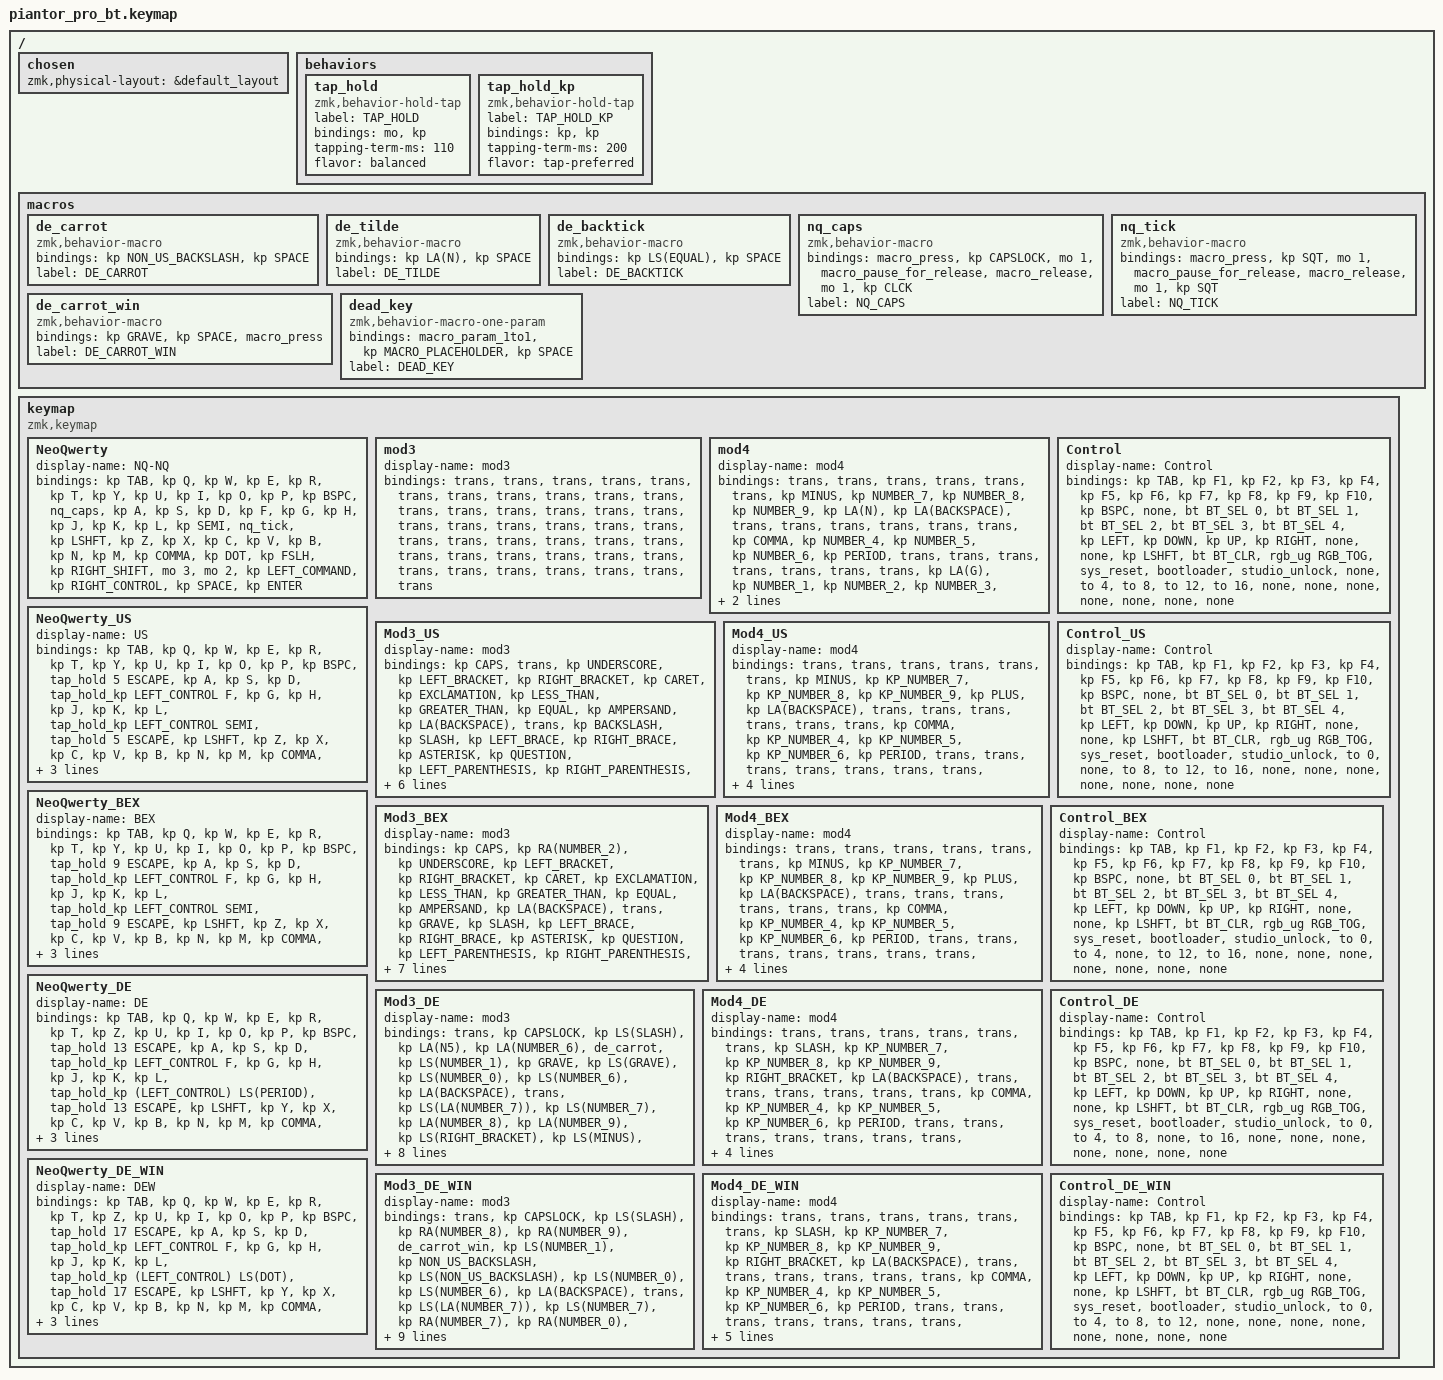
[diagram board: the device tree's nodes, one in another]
/*
 * Copyright (c) 2020 The ZMK Contributors
 *
 * SPDX-License-Identifier: MIT
 */

#include <behaviors.dtsi>
#include <dt-bindings/zmk/bt.h>
#include <dt-bindings/zmk/keys.h>
#include <dt-bindings/zmk/rgb.h>

/ {
    chosen { zmk,physical-layout = &default_layout; };
};

/ {
    behaviors {
        tap_hold: tap_hold {
            compatible = "zmk,behavior-hold-tap";
            label = "TAP_HOLD";
            bindings = <&mo>, <&kp>;

            #binding-cells = <2>;
            tapping-term-ms = <110>;
            flavor = "balanced";
        };

        tap_hold_kp: tap_hold_kp {
            compatible = "zmk,behavior-hold-tap";
            label = "TAP_HOLD_KP";
            bindings = <&kp>, <&kp>;

            #binding-cells = <2>;
            tapping-term-ms = <200>;
            flavor = "tap-preferred";
        };
    };

    macros {
        de_carrot: de_carrot {
            compatible = "zmk,behavior-macro";
            #binding-cells = <0>;
            bindings = <&kp NON_US_BACKSLASH &kp SPACE>;
            label = "DE_CARROT";
        };

        de_tilde: de_tilde {
            compatible = "zmk,behavior-macro";
            #binding-cells = <0>;
            bindings = <&kp LA(N) &kp SPACE>;
            label = "DE_TILDE";
        };

        de_backtick: de_backtick {
            compatible = "zmk,behavior-macro";
            #binding-cells = <0>;
            bindings = <&kp LS(EQUAL) &kp SPACE>;
            label = "DE_BACKTICK";
        };

        nq_caps: nq_caps {
            compatible = "zmk,behavior-macro";
            #binding-cells = <0>;
            bindings =
                <&macro_press>,
                <&kp CAPSLOCK &mo 1>,
                <&macro_pause_for_release>,
                <&macro_release>,
                <&mo 1 &kp CLCK>;

            label = "NQ_CAPS";
        };

        nq_tick: nq_tick {
            compatible = "zmk,behavior-macro";
            #binding-cells = <0>;
            bindings =
                <&macro_press>,
                <&kp SQT &mo 1>,
                <&macro_pause_for_release>,
                <&macro_release>,
                <&mo 1 &kp SQT>;

            label = "NQ_TICK";
        };

        de_carrot_win: de_carrot_win {
            compatible = "zmk,behavior-macro";
            #binding-cells = <0>;
            bindings = <&kp GRAVE &kp SPACE>, <&macro_press>;

            label = "DE_CARROT_WIN";
        };

        dead_key: dead_key {
            compatible = "zmk,behavior-macro-one-param";
            #binding-cells = <1>;
            bindings = <&macro_param_1to1 &kp MACRO_PLACEHOLDER &kp SPACE>;
            label = "DEAD_KEY";
        };
    };

    keymap {
        compatible = "zmk,keymap";

        NeoQwerty {
            display-name = "NQ-NQ";
            bindings = <
&kp TAB  &kp Q  &kp W  &kp E  &kp R  &kp T  &kp Y  &kp U  &kp I  &kp O  &kp P  &kp BSPC  &nq_caps  &kp A  &kp S  &kp D  &kp F  &kp G  &kp H  &kp J  &kp K  &kp L  &kp SEMI  &nq_tick  &kp LSHFT  &kp Z  &kp X  &kp C  &kp V  &kp B  &kp N  &kp M  &kp COMMA  &kp DOT  &kp FSLH  &kp RIGHT_SHIFT  &mo 3  &mo 2  &kp LEFT_COMMAND  &kp RIGHT_CONTROL  &kp SPACE  &kp ENTER
            >;
        };

        mod3 {
            display-name = "mod3";
            bindings = <
&trans  &trans  &trans  &trans  &trans  &trans  &trans  &trans  &trans  &trans  &trans  &trans  &trans  &trans  &trans  &trans  &trans  &trans  &trans  &trans  &trans  &trans  &trans  &trans  &trans  &trans  &trans  &trans  &trans  &trans  &trans  &trans  &trans  &trans  &trans  &trans  &trans  &trans  &trans  &trans  &trans  &trans
            >;
        };

        mod4 {
            display-name = "mod4";
            bindings = <
&trans  &trans  &trans  &trans  &trans  &trans  &kp MINUS  &kp NUMBER_7  &kp NUMBER_8  &kp NUMBER_9  &kp LA(N)  &kp LA(BACKSPACE)  &trans  &trans  &trans  &trans  &trans  &trans  &kp COMMA  &kp NUMBER_4  &kp NUMBER_5  &kp NUMBER_6  &kp PERIOD  &trans  &trans  &trans  &trans  &trans  &trans  &trans  &kp LA(G)  &kp NUMBER_1  &kp NUMBER_2  &kp NUMBER_3  &kp SLASH  &kp KP_NUMLOCK  &trans  &trans  &trans  &kp SPACE  &kp NUMBER_0  &trans
            >;
        };

        Control {
            display-name = "Control";
            bindings = <
&kp TAB  &kp F1  &kp F2  &kp F3  &kp F4  &kp F5  &kp F6  &kp F7  &kp F8  &kp F9  &kp F10  &kp BSPC  &none  &bt BT_SEL 0  &bt BT_SEL 1  &bt BT_SEL 2  &bt BT_SEL 3  &bt BT_SEL 4  &kp LEFT  &kp DOWN  &kp UP  &kp RIGHT  &none  &none  &kp LSHFT  &bt BT_CLR  &rgb_ug RGB_TOG  &sys_reset  &bootloader  &studio_unlock  &none  &to 4  &to 8  &to 12  &to 16  &none  &none  &none  &none  &none  &none  &none
            >;
        };

        NeoQwerty_US {
            display-name = "US";
            bindings = <
&kp TAB  &kp Q  &kp W  &kp E  &kp R  &kp T  &kp Y  &kp U  &kp I  &kp O  &kp P  &kp BSPC  &tap_hold 5 ESCAPE  &kp A  &kp S  &kp D  &tap_hold_kp LEFT_CONTROL F  &kp G  &kp H  &kp J  &kp K  &kp L  &tap_hold_kp LEFT_CONTROL SEMI  &tap_hold 5 ESCAPE  &kp LSHFT  &kp Z  &kp X  &kp C  &kp V  &kp B  &kp N  &kp M  &kp COMMA  &kp DOT  &kp FSLH  &kp RIGHT_SHIFT  &mo 7  &mo 6  &kp LEFT_COMMAND  &kp LEFT_ALT  &kp SPACE  &kp ENTER
            >;
        };

        Mod3_US {
            display-name = "mod3";
            bindings = <
&kp CAPS  &trans  &kp UNDERSCORE  &kp LEFT_BRACKET  &kp RIGHT_BRACKET  &kp CARET  &kp EXCLAMATION  &kp LESS_THAN  &kp GREATER_THAN  &kp EQUAL  &kp AMPERSAND  &kp LA(BACKSPACE)  &trans  &kp BACKSLASH  &kp SLASH  &kp LEFT_BRACE  &kp RIGHT_BRACE  &kp ASTERISK  &kp QUESTION  &kp LEFT_PARENTHESIS  &kp RIGHT_PARENTHESIS  &kp MINUS  &kp COLON  &trans  &kp RA(S)  &kp HASH  &kp DOLLAR  &kp PIPE  &kp TILDE  &kp GRAVE  &kp PLUS  &kp PERCENT  &kp DOUBLE_QUOTES  &kp SINGLE_QUOTE  &kp SEMICOLON  &kp AT_SIGN  &trans  &trans  &trans  &trans  &trans  &trans
            >;
        };

        Mod4_US {
            display-name = "mod4";
            bindings = <
&trans  &trans  &trans  &trans  &trans  &trans  &kp MINUS  &kp KP_NUMBER_7  &kp KP_NUMBER_8  &kp KP_NUMBER_9  &kp PLUS  &kp LA(BACKSPACE)  &trans  &trans  &trans  &trans  &trans  &trans  &kp COMMA  &kp KP_NUMBER_4  &kp KP_NUMBER_5  &kp KP_NUMBER_6  &kp PERIOD  &trans  &trans  &trans  &trans  &trans  &trans  &trans  &kp ASTERISK  &kp KP_NUMBER_1  &kp KP_NUMBER_2  &kp KP_NUMBER_3  &kp SLASH  &kp KP_NUMLOCK  &trans  &trans  &trans  &trans  &kp KP_NUMBER_0  &trans
            >;
        };

        Control_US {
            display-name = "Control";
            bindings = <
&kp TAB  &kp F1  &kp F2  &kp F3  &kp F4  &kp F5  &kp F6  &kp F7  &kp F8  &kp F9  &kp F10  &kp BSPC  &none  &bt BT_SEL 0  &bt BT_SEL 1  &bt BT_SEL 2  &bt BT_SEL 3  &bt BT_SEL 4  &kp LEFT  &kp DOWN  &kp UP  &kp RIGHT  &none  &none  &kp LSHFT  &bt BT_CLR  &rgb_ug RGB_TOG  &sys_reset  &bootloader  &studio_unlock  &to 0  &none  &to 8  &to 12  &to 16  &none  &none  &none  &none  &none  &none  &none
            >;
        };

        NeoQwerty_BEX {
            display-name = "BEX";
            bindings = <
&kp TAB  &kp Q  &kp W  &kp E  &kp R  &kp T  &kp Y  &kp U  &kp I  &kp O  &kp P  &kp BSPC  &tap_hold 9 ESCAPE  &kp A  &kp S  &kp D  &tap_hold_kp LEFT_CONTROL F  &kp G  &kp H  &kp J  &kp K  &kp L  &tap_hold_kp LEFT_CONTROL SEMI  &tap_hold 9 ESCAPE  &kp LSHFT  &kp Z  &kp X  &kp C  &kp V  &kp B  &kp N  &kp M  &kp COMMA  &kp DOT  &kp FSLH  &kp RIGHT_SHIFT  &mo 11  &mo 10  &kp LEFT_COMMAND  &kp LEFT_ALT  &kp SPACE  &kp ENTER
            >;
        };

        Mod3_BEX {
            display-name = "mod3";
            bindings = <
&kp CAPS  &kp RA(NUMBER_2)  &kp UNDERSCORE  &kp LEFT_BRACKET  &kp RIGHT_BRACKET  &kp CARET  &kp EXCLAMATION  &kp LESS_THAN  &kp GREATER_THAN  &kp EQUAL  &kp AMPERSAND  &kp LA(BACKSPACE)  &trans  &kp GRAVE  &kp SLASH  &kp LEFT_BRACE  &kp RIGHT_BRACE  &kp ASTERISK  &kp QUESTION  &kp LEFT_PARENTHESIS  &kp RIGHT_PARENTHESIS  &kp MINUS  &kp COLON  &trans  &kp RA(S)  &kp BACKSLASH  &kp DOLLAR  &kp LS(NON_US_BACKSLASH)  &kp LS(BACKSLASH)  &kp RA(RS(SQT))  &kp PLUS  &kp PERCENT  &kp RS(NUMBER_2)  &kp SINGLE_QUOTE  &kp SEMICOLON  &kp RS(SQT)  &trans  &trans  &trans  &trans  &trans  &trans
            >;
        };

        Mod4_BEX {
            display-name = "mod4";
            bindings = <
&trans  &trans  &trans  &trans  &trans  &trans  &kp MINUS  &kp KP_NUMBER_7  &kp KP_NUMBER_8  &kp KP_NUMBER_9  &kp PLUS  &kp LA(BACKSPACE)  &trans  &trans  &trans  &trans  &trans  &trans  &kp COMMA  &kp KP_NUMBER_4  &kp KP_NUMBER_5  &kp KP_NUMBER_6  &kp PERIOD  &trans  &trans  &trans  &trans  &trans  &trans  &trans  &kp ASTERISK  &kp KP_NUMBER_1  &kp KP_NUMBER_2  &kp KP_NUMBER_3  &kp SLASH  &kp KP_NUMLOCK  &trans  &trans  &trans  &trans  &kp KP_NUMBER_0  &trans
            >;
        };

        Control_BEX {
            display-name = "Control";
            bindings = <
&kp TAB  &kp F1  &kp F2  &kp F3  &kp F4  &kp F5  &kp F6  &kp F7  &kp F8  &kp F9  &kp F10  &kp BSPC  &none  &bt BT_SEL 0  &bt BT_SEL 1  &bt BT_SEL 2  &bt BT_SEL 3  &bt BT_SEL 4  &kp LEFT  &kp DOWN  &kp UP  &kp RIGHT  &none  &none  &kp LSHFT  &bt BT_CLR  &rgb_ug RGB_TOG  &sys_reset  &bootloader  &studio_unlock  &to 0  &to 4  &none  &to 12  &to 16  &none  &none  &none  &none  &none  &none  &none
            >;
        };

        NeoQwerty_DE {
            display-name = "DE";
            bindings = <
&kp TAB  &kp Q  &kp W  &kp E  &kp R  &kp T  &kp Z  &kp U  &kp I  &kp O  &kp P  &kp BSPC  &tap_hold 13 ESCAPE  &kp A  &kp S  &kp D  &tap_hold_kp LEFT_CONTROL F  &kp G  &kp H  &kp J  &kp K  &kp L  &tap_hold_kp (LEFT_CONTROL) LS(PERIOD)  &tap_hold 13 ESCAPE  &kp LSHFT  &kp Y  &kp X  &kp C  &kp V  &kp B  &kp N  &kp M  &kp COMMA  &kp DOT  &kp FSLH  &kp RIGHT_SHIFT  &mo 15  &mo 14  &kp LEFT_COMMAND  &kp LEFT_ALT  &kp SPACE  &kp ENTER
            >;
        };

        Mod3_DE {
            display-name = "mod3";
            bindings = <
&trans  &kp CAPSLOCK  &kp LS(SLASH)  &kp LA(N5)  &kp LA(NUMBER_6)  &de_carrot  &kp LS(NUMBER_1)  &kp GRAVE  &kp LS(GRAVE)  &kp LS(NUMBER_0)  &kp LS(NUMBER_6)  &kp LA(BACKSPACE)  &trans  &kp LS(LA(NUMBER_7))  &kp LS(NUMBER_7)  &kp LA(NUMBER_8)  &kp LA(NUMBER_9)  &kp LS(RIGHT_BRACKET)  &kp LS(MINUS)  &kp LS(N8)  &kp LS(N9)  &kp SLASH  &kp LS(PERIOD)  &trans  &trans  &kp NON_US_BACKSLASH  &kp LS(NUMBER_4)  &kp LA(NUMBER_7)  &de_tilde  &de_backtick  &kp RIGHT_BRACKET  &kp LS(NUMBER_5)  &kp RS(NUMBER_2)  &kp LS(BACKSLASH)  &kp LS(COMMA)  &kp LA(L)  &trans  &trans  &trans  &trans  &trans  &trans
            >;
        };

        Mod4_DE {
            display-name = "mod4";
            bindings = <
&trans  &trans  &trans  &trans  &trans  &trans  &kp SLASH  &kp KP_NUMBER_7  &kp KP_NUMBER_8  &kp KP_NUMBER_9  &kp RIGHT_BRACKET  &kp LA(BACKSPACE)  &trans  &trans  &trans  &trans  &trans  &trans  &kp COMMA  &kp KP_NUMBER_4  &kp KP_NUMBER_5  &kp KP_NUMBER_6  &kp PERIOD  &trans  &trans  &trans  &trans  &trans  &trans  &trans  &kp LS(RIGHT_BRACKET)  &kp KP_NUMBER_1  &kp KP_NUMBER_2  &kp KP_NUMBER_3  &kp LS(NUMBER_7)  &kp KP_NUMLOCK  &trans  &trans  &trans  &trans  &kp KP_NUMBER_0  &trans
            >;
        };

        Control_DE {
            display-name = "Control";
            bindings = <
&kp TAB  &kp F1  &kp F2  &kp F3  &kp F4  &kp F5  &kp F6  &kp F7  &kp F8  &kp F9  &kp F10  &kp BSPC  &none  &bt BT_SEL 0  &bt BT_SEL 1  &bt BT_SEL 2  &bt BT_SEL 3  &bt BT_SEL 4  &kp LEFT  &kp DOWN  &kp UP  &kp RIGHT  &none  &none  &kp LSHFT  &bt BT_CLR  &rgb_ug RGB_TOG  &sys_reset  &bootloader  &studio_unlock  &to 0  &to 4  &to 8  &none  &to 16  &none  &none  &none  &none  &none  &none  &none
            >;
        };

        NeoQwerty_DE_WIN {
            display-name = "DEW";
            bindings = <
&kp TAB  &kp Q  &kp W  &kp E  &kp R  &kp T  &kp Z  &kp U  &kp I  &kp O  &kp P  &kp BSPC  &tap_hold 17 ESCAPE  &kp A  &kp S  &kp D  &tap_hold_kp LEFT_CONTROL F  &kp G  &kp H  &kp J  &kp K  &kp L  &tap_hold_kp (LEFT_CONTROL) LS(DOT)  &tap_hold 17 ESCAPE  &kp LSHFT  &kp Y  &kp X  &kp C  &kp V  &kp B  &kp N  &kp M  &kp COMMA  &kp DOT  &kp FSLH  &kp RIGHT_SHIFT  &mo 19  &mo 18  &kp LEFT_COMMAND  &kp LEFT_ALT  &kp SPACE  &kp ENTER
            >;
        };

        Mod3_DE_WIN {
            display-name = "mod3";
            bindings = <
&trans  &kp CAPSLOCK  &kp LS(SLASH)  &kp RA(NUMBER_8)  &kp RA(NUMBER_9)  &de_carrot_win  &kp LS(NUMBER_1)  &kp NON_US_BACKSLASH  &kp LS(NON_US_BACKSLASH)  &kp LS(NUMBER_0)  &kp LS(NUMBER_6)  &kp LA(BACKSPACE)  &trans  &kp LS(LA(NUMBER_7))  &kp LS(NUMBER_7)  &kp RA(NUMBER_7)  &kp RA(NUMBER_0)  &kp LS(RIGHT_BRACKET)  &kp LS(MINUS)  &kp LS(N8)  &kp LS(N9)  &kp SLASH  &kp LS(PERIOD)  &trans  &trans  &kp NON_US_BACKSLASH  &kp LS(NUMBER_4)  &kp LA(NUMBER_7)  &de_tilde  &de_backtick  &kp RIGHT_BRACKET  &kp LS(NUMBER_5)  &kp RS(NUMBER_2)  &kp LS(BACKSLASH)  &kp LS(COMMA)  &kp RA(Q)  &trans  &trans  &trans  &trans  &trans  &trans
            >;
        };

        Mod4_DE_WIN {
            display-name = "mod4";
            bindings = <
&trans  &trans  &trans  &trans  &trans  &trans  &kp SLASH  &kp KP_NUMBER_7  &kp KP_NUMBER_8  &kp KP_NUMBER_9  &kp RIGHT_BRACKET  &kp LA(BACKSPACE)  &trans  &trans  &trans  &trans  &trans  &trans  &kp COMMA  &kp KP_NUMBER_4  &kp KP_NUMBER_5  &kp KP_NUMBER_6  &kp PERIOD  &trans  &trans  &trans  &trans  &trans  &trans  &trans  &kp LS(RIGHT_BRACKET)  &kp KP_NUMBER_1  &kp KP_NUMBER_2  &kp KP_NUMBER_3  &kp LS(NUMBER_7)  &kp KP_NUMLOCK  &trans  &trans  &trans  &trans  &kp KP_NUMBER_0  &kp KP_NUMLOCK
            >;
        };

        Control_DE_WIN {
            display-name = "Control";
            bindings = <
&kp TAB  &kp F1  &kp F2  &kp F3  &kp F4  &kp F5  &kp F6  &kp F7  &kp F8  &kp F9  &kp F10  &kp BSPC  &none  &bt BT_SEL 0  &bt BT_SEL 1  &bt BT_SEL 2  &bt BT_SEL 3  &bt BT_SEL 4  &kp LEFT  &kp DOWN  &kp UP  &kp RIGHT  &none  &none  &kp LSHFT  &bt BT_CLR  &rgb_ug RGB_TOG  &sys_reset  &bootloader  &studio_unlock  &to 0  &to 4  &to 8  &to 12  &none  &none  &none  &none  &none  &none  &none  &none
            >;
        };
    };
};
